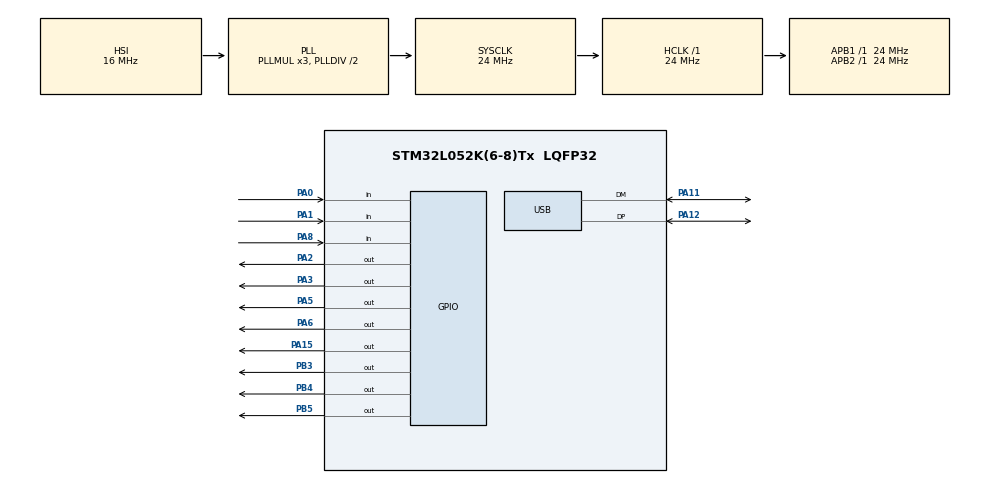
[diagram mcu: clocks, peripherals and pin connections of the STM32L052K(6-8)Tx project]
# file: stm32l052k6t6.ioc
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Mcu.Family=STM32L0
Mcu.Name=STM32L052K(6-8)Tx
Mcu.Package=LQFP32
NVIC.RTC_IRQn=true\:0\:0\:false
NVIC.USB_IRQn=true\:0\:0\:false
PA0.Signal=GPIO_Input
PA1.Signal=GPIO_Input
PA11.Mode=Device
PA11.Signal=USB_DM
PA12.Mode=Device
PA12.Signal=USB_DP
PA13.Mode=Serial_Wire
PA13.Signal=SYS_SWDIO
PA14.Mode=Serial_Wire
PA14.Signal=SYS_SWCLK
PA15.Signal=GPIO_Output
PA2.Signal=GPIO_Output
PA3.Signal=GPIO_Output
PA5.Signal=GPIO_Output
PA6.Signal=GPIO_Output
PA8.Signal=GPIO_Input
PB3.Signal=GPIO_Output
PB4.Signal=GPIO_Output
PB5.Signal=GPIO_Output
ProjectManager.HeapSize=0x400
ProjectManager.StackSize=0x200
ProjectManager.TargetToolchain=MDK-ARM V5
RCC.AHBFreq_Value=24000000
RCC.APB1Freq_Value=24000000
RCC.APB1TimFreq_Value=24000000
RCC.APB2Freq_Value=24000000
RCC.APB2TimFreq_Value=24000000
RCC.HCLKFreq_Value=24000000
RCC.HSI16_VALUE=16000000
RCC.HSI48MClockSelection=RCC_USBCLKSOURCE_HSI48
RCC.HSI48_VALUE=48000000
RCC.HSI_VALUE=16000000
RCC.LSE_VALUE=32768
RCC.MSI_VALUE=2097000
RCC.SYSCLKFreq_VALUE=24000000
RCC.SYSCLKSource=RCC_SYSCLKSOURCE_PLLCLK
RCC.VCOOutputFreq_Value=48000000
RTC.WakeUpClock=RTC_WAKEUPCLOCK_RTCCLK_DIV4
RTC.WakeUpCounter=4625
USB_DEVICE.USBD_DFU_APP_DEFAULT_ADD=0x08004000
USB_DEVICE.USBD_DFU_MEDIA=@Internal Flash   /0x08004000/1*16Kg
USB_DEVICE.USBD_HandleTypeDef=hUsbDeviceFS
USB_DEVICE.VirtualMode=Dfu
USB_DEVICE.VirtualModeFS=Dfu_FS
VP_RTC_VS_RTC_WakeUp_intern.Mode=WakeUp
VP_USB_DEVICE_VS_USB_DEVICE_DFU_FS.Mode=DFU_FS
board=stm32l052k6t6

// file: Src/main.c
/**
  ******************************************************************************
  * File Name          : main.c
  * Description        : Main program body
  ******************************************************************************
  *
  * COPYRIGHT(c) 2016 STMicroelectronics
  *
  * Redistribution and use in source and binary forms, with or without modification,
  * are permitted provided that the following conditions are met:
  *   1. Redistributions of source code must retain the above copyright notice,
  *      this list of conditions and the following disclaimer.
  *   2. Redistributions in binary form must reproduce the above copyright notice,
  *      this list of conditions and the following disclaimer in the documentation
  *      and/or other materials provided with the distribution.
  *   3. Neither the name of STMicroelectronics nor the names of its contributors
  *      may be used to endorse or promote products derived from this software
  *      without specific prior written permission.
  *
  * THIS SOFTWARE IS PROVIDED BY THE COPYRIGHT HOLDERS AND CONTRIBUTORS "AS IS"
  * AND ANY EXPRESS OR IMPLIED WARRANTIES, INCLUDING, BUT NOT LIMITED TO, THE
  * IMPLIED WARRANTIES OF MERCHANTABILITY AND FITNESS FOR A PARTICULAR PURPOSE ARE
  * DISCLAIMED. IN NO EVENT SHALL THE COPYRIGHT HOLDER OR CONTRIBUTORS BE LIABLE
  * FOR ANY DIRECT, INDIRECT, INCIDENTAL, SPECIAL, EXEMPLARY, OR CONSEQUENTIAL
  * DAMAGES (INCLUDING, BUT NOT LIMITED TO, PROCUREMENT OF SUBSTITUTE GOODS OR
  * SERVICES; LOSS OF USE, DATA, OR PROFITS; OR BUSINESS INTERRUPTION) HOWEVER
  * CAUSED AND ON ANY THEORY OF LIABILITY, WHETHER IN CONTRACT, STRICT LIABILITY,
  * OR TORT (INCLUDING NEGLIGENCE OR OTHERWISE) ARISING IN ANY WAY OUT OF THE USE
  * OF THIS SOFTWARE, EVEN IF ADVISED OF THE POSSIBILITY OF SUCH DAMAGE.
  *
  ******************************************************************************
  */
#include "stm32l0xx_hal.h"
#include "rtc.h"
#include "usb_device.h"
#include "gpio.h"

/* USER CODE BEGIN PV */
/* Private variables ---------------------------------------------------------*/
typedef void (*pFunction)(void);
pFunction JumpToApplication;

/* USER CODE END PV */

void SystemClock_Config(void);

/* USER CODE BEGIN PFP */
/* Private function prototypes -----------------------------------------------*/

/* USER CODE END PFP */

int main(void)
{

  /* MCU Configuration----------------------------------------------------------*/

  /* Reset of all peripherals, Initializes the Flash interface and the Systick. */
  HAL_Init();

  /* Configure the system clock */
  SystemClock_Config();

  /* Initialize all configured peripherals */
  MX_GPIO_Init();
  MX_USB_DEVICE_Init();
  MX_RTC_Init();

  /* USER CODE BEGIN 2 */

	HAL_GPIO_WritePin(GPIOA, GPIO_PIN_5, GPIO_PIN_SET);
	HAL_GPIO_WritePin(GPIOA, GPIO_PIN_6, GPIO_PIN_SET);

  /* USER CODE END 2 */

  /* Infinite loop */
  /* USER CODE BEGIN WHILE */
  while (1)
  {
  /* Check if the KEY Button is pressed */
		if ((HAL_GPIO_ReadPin(GPIOA, GPIO_PIN_0) == GPIO_PIN_RESET) ||	// No USB power or
				(HAL_GPIO_ReadPin(GPIOA, GPIO_PIN_1) == GPIO_PIN_RESET))		// test button pressed
		{
			/* Test if user code is programmed starting from address 0x08007000 */
			if(((*(__IO uint32_t*)USBD_DFU_APP_DEFAULT_ADD) & 0x2FFE0000 ) == 0x20000000)
			{
				/* Jump to user application */
				uint32_t JumpAddress = *(__IO uint32_t*) (USBD_DFU_APP_DEFAULT_ADD + 4);
				JumpToApplication = (pFunction) JumpAddress;

				/* Initialize user application's Stack Pointer */
				__set_MSP(*(__IO uint32_t*) USBD_DFU_APP_DEFAULT_ADD);
				JumpToApplication();
			}
		}

  /* USER CODE END WHILE */

  }

}

/** System Clock Configuration
*/
void SystemClock_Config(void)
{

  RCC_OscInitTypeDef RCC_OscInitStruct;
  RCC_ClkInitTypeDef RCC_ClkInitStruct;
  RCC_PeriphCLKInitTypeDef PeriphClkInit;

  __PWR_CLK_ENABLE();

  __HAL_PWR_VOLTAGESCALING_CONFIG(PWR_REGULATOR_VOLTAGE_SCALE1);

  RCC_OscInitStruct.OscillatorType = RCC_OSCILLATORTYPE_HSI|RCC_OSCILLATORTYPE_LSI
                              |RCC_OSCILLATORTYPE_HSI48;
  RCC_OscInitStruct.HSIState = RCC_HSI_ON;
  RCC_OscInitStruct.HSICalibrationValue = 16;
  RCC_OscInitStruct.LSIState = RCC_LSI_ON;
  RCC_OscInitStruct.HSI48State = RCC_HSI48_ON;
  RCC_OscInitStruct.PLL.PLLState = RCC_PLL_ON;
  RCC_OscInitStruct.PLL.PLLSource = RCC_PLLSOURCE_HSI;
  RCC_OscInitStruct.PLL.PLLMUL = RCC_PLLMUL_3;
  RCC_OscInitStruct.PLL.PLLDIV = RCC_PLLDIV_2;
  HAL_RCC_OscConfig(&RCC_OscInitStruct);

  RCC_ClkInitStruct.ClockType = RCC_CLOCKTYPE_HCLK|RCC_CLOCKTYPE_SYSCLK
                              |RCC_CLOCKTYPE_PCLK1|RCC_CLOCKTYPE_PCLK2;
  RCC_ClkInitStruct.SYSCLKSource = RCC_SYSCLKSOURCE_PLLCLK;
  RCC_ClkInitStruct.AHBCLKDivider = RCC_SYSCLK_DIV1;
  RCC_ClkInitStruct.APB1CLKDivider = RCC_HCLK_DIV1;
  RCC_ClkInitStruct.APB2CLKDivider = RCC_HCLK_DIV1;
  HAL_RCC_ClockConfig(&RCC_ClkInitStruct, FLASH_LATENCY_1);

  PeriphClkInit.PeriphClockSelection = RCC_PERIPHCLK_RTC|RCC_PERIPHCLK_USB;
  PeriphClkInit.RTCClockSelection = RCC_RTCCLKSOURCE_LSI;
  PeriphClkInit.UsbClockSelection = RCC_USBCLKSOURCE_HSI48;
  HAL_RCCEx_PeriphCLKConfig(&PeriphClkInit);

  HAL_SYSTICK_Config(HAL_RCC_GetHCLKFreq()/1000);

  HAL_SYSTICK_CLKSourceConfig(SYSTICK_CLKSOURCE_HCLK);

  /* SysTick_IRQn interrupt configuration */
  HAL_NVIC_SetPriority(SysTick_IRQn, 0, 0);
}

/************************ (C) COPYRIGHT STMicroelectronics *****END OF FILE****/
